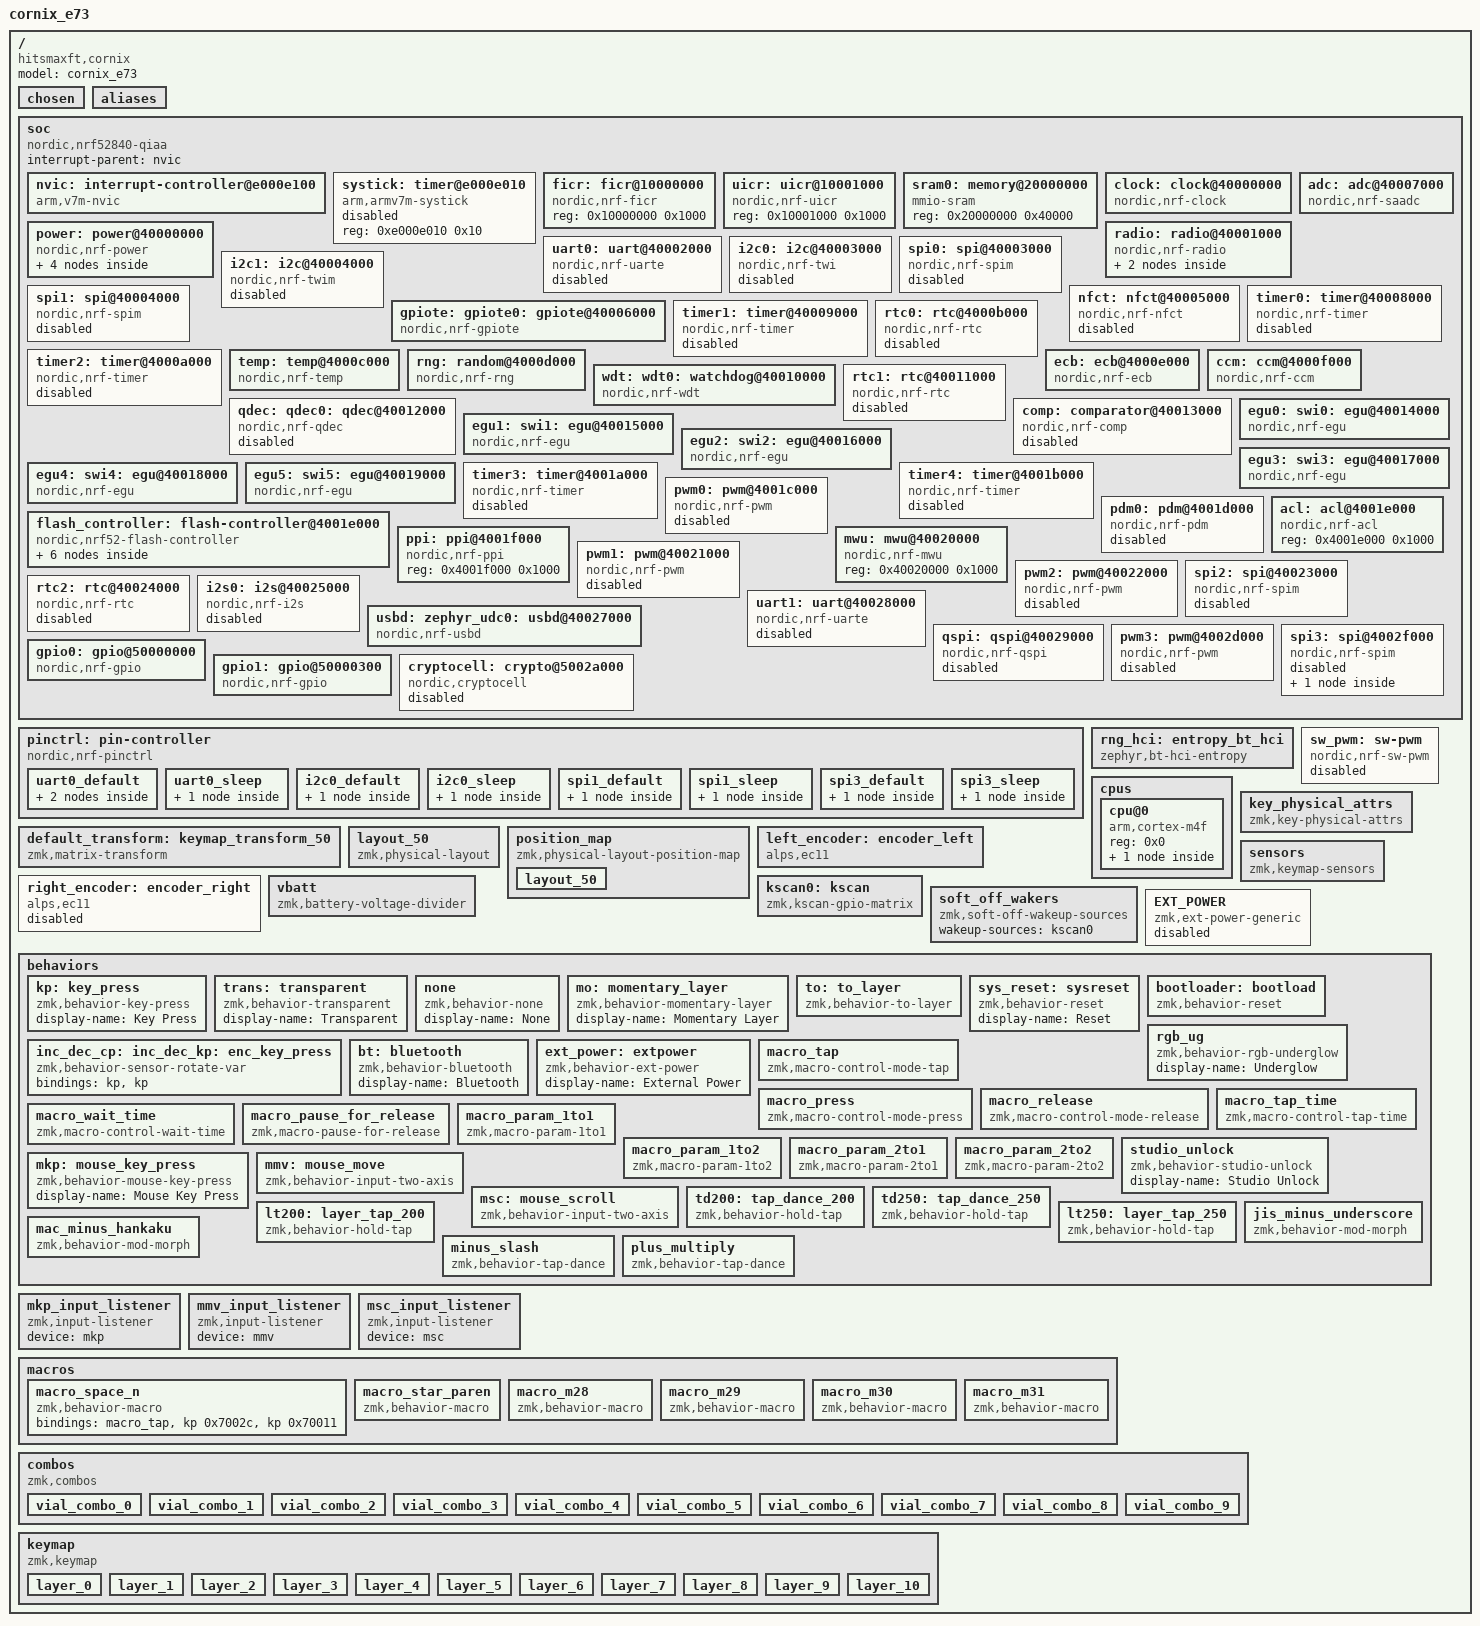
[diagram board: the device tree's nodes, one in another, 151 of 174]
/dts-v1/;

/ {
	#address-cells = < 0x1 >;
	#size-cells = < 0x1 >;
	model = "cornix_e73";
	compatible = "hitsmaxft,cornix";
	chosen {
		zephyr,bt-hci = &bt_hci_controller;
		zephyr,entropy = &rng;
		zephyr,flash-controller = &flash_controller;
		zephyr,code-partition = &code_partition;
		zephyr,sram = &sram0;
		zephyr,flash = &flash0;
		zmk,battery = &vbatt;
		zmk,kscan = &kscan0;
		zmk,physical-layout = &layout_50;
	};
	aliases {
	};
	soc {
		#address-cells = < 0x1 >;
		#size-cells = < 0x1 >;
		compatible = "nordic,nrf52840-qiaa", "nordic,nrf52840", "nordic,nrf52", "simple-bus";
		interrupt-parent = < &nvic >;
		ranges;
		nvic: interrupt-controller@e000e100 {
			#address-cells = < 0x1 >;
			compatible = "arm,v7m-nvic";
			reg = < 0xe000e100 0xc00 >;
			interrupt-controller;
			#interrupt-cells = < 0x2 >;
			arm,num-irq-priority-bits = < 0x3 >;
			phandle = < 0x1 >;
		};
		systick: timer@e000e010 {
			compatible = "arm,armv7m-systick";
			reg = < 0xe000e010 0x10 >;
			status = "disabled";
		};
		ficr: ficr@10000000 {
			compatible = "nordic,nrf-ficr";
			reg = < 0x10000000 0x1000 >;
			#nordic,ficr-cells = < 0x1 >;
			status = "okay";
		};
		uicr: uicr@10001000 {
			compatible = "nordic,nrf-uicr";
			reg = < 0x10001000 0x1000 >;
			status = "okay";
		};
		sram0: memory@20000000 {
			compatible = "mmio-sram";
			reg = < 0x20000000 0x40000 >;
		};
		clock: clock@40000000 {
			compatible = "nordic,nrf-clock";
			reg = < 0x40000000 0x1000 >;
			interrupts = < 0x0 0x1 >;
			status = "okay";
		};
		power: power@40000000 {
			compatible = "nordic,nrf-power";
			reg = < 0x40000000 0x1000 >;
			interrupts = < 0x0 0x1 >;
			status = "okay";
			#address-cells = < 0x1 >;
			#size-cells = < 0x1 >;
			gpregret1: gpregret1@4000051c {
				#address-cells = < 0x1 >;
				#size-cells = < 0x1 >;
				compatible = "nordic,nrf-gpregret";
				reg = < 0x4000051c 0x1 >;
				status = "okay";
			};
			gpregret2: gpregret2@40000520 {
				#address-cells = < 0x1 >;
				#size-cells = < 0x1 >;
				compatible = "nordic,nrf-gpregret";
				reg = < 0x40000520 0x1 >;
				status = "okay";
			};
			reg1: regulator@40000578 {
				compatible = "nordic,nrf5x-regulator";
				reg = < 0x40000578 0x1 >;
				regulator-name = "REG1";
				regulator-initial-mode = < 0x0 >;
			};
			reg0: regulator@40000580 {
				compatible = "nordic,nrf52x-regulator-hv";
				reg = < 0x40000580 0x1 >;
				regulator-name = "REG0";
				status = "disabled";
			};
		};
		radio: radio@40001000 {
			compatible = "nordic,nrf-radio";
			reg = < 0x40001000 0x1000 >;
			interrupts = < 0x1 0x1 >;
			status = "okay";
			ieee802154-supported;
			ble-2mbps-supported;
			ble-coded-phy-supported;
			tx-high-power-supported;
			ieee802154: ieee802154 {
				compatible = "nordic,nrf-ieee802154";
				status = "disabled";
			};
			bt_hci_controller: bt_hci_controller {
				compatible = "zephyr,bt-hci-ll-sw-split";
				status = "okay";
			};
		};
		uart0: uart@40002000 {
			compatible = "nordic,nrf-uarte";
			reg = < 0x40002000 0x1000 >;
			interrupts = < 0x2 0x1 >;
			status = "disabled";
			current-speed = < 0x1c200 >;
			pinctrl-0 = < &uart0_default >;
			pinctrl-1 = < &uart0_sleep >;
			pinctrl-names = "default", "sleep";
		};
		i2c0: i2c@40003000 {
			compatible = "nordic,nrf-twi";
			#address-cells = < 0x1 >;
			#size-cells = < 0x0 >;
			reg = < 0x40003000 0x1000 >;
			interrupts = < 0x3 0x1 >;
			easydma-maxcnt-bits = < 0x10 >;
			status = "disabled";
			zephyr,pm-device-runtime-auto;
			pinctrl-0 = < &i2c0_default >;
			pinctrl-1 = < &i2c0_sleep >;
			pinctrl-names = "default", "sleep";
		};
		spi0: spi@40003000 {
			compatible = "nordic,nrf-spim";
			#address-cells = < 0x1 >;
			#size-cells = < 0x0 >;
			reg = < 0x40003000 0x1000 >;
			interrupts = < 0x3 0x1 >;
			max-frequency = < 0x7a1200 >;
			easydma-maxcnt-bits = < 0x10 >;
			status = "disabled";
		};
		i2c1: i2c@40004000 {
			compatible = "nordic,nrf-twim";
			#address-cells = < 0x1 >;
			#size-cells = < 0x0 >;
			reg = < 0x40004000 0x1000 >;
			interrupts = < 0x4 0x1 >;
			easydma-maxcnt-bits = < 0x10 >;
			status = "disabled";
			zephyr,pm-device-runtime-auto;
		};
		spi1: spi@40004000 {
			compatible = "nordic,nrf-spim";
			#address-cells = < 0x1 >;
			#size-cells = < 0x0 >;
			reg = < 0x40004000 0x1000 >;
			interrupts = < 0x4 0x1 >;
			max-frequency = < 0x7a1200 >;
			easydma-maxcnt-bits = < 0x10 >;
			status = "disabled";
			pinctrl-0 = < &spi1_default >;
			pinctrl-1 = < &spi1_sleep >;
			pinctrl-names = "default", "sleep";
		};
		nfct: nfct@40005000 {
			compatible = "nordic,nrf-nfct";
			reg = < 0x40005000 0x1000 >;
			interrupts = < 0x5 0x1 >;
			status = "disabled";
		};
		gpiote: gpiote0: gpiote@40006000 {
			compatible = "nordic,nrf-gpiote";
			reg = < 0x40006000 0x1000 >;
			interrupts = < 0x6 0x5 >;
			status = "okay";
			instance = < 0x0 >;
			phandle = < 0xa >;
		};
		adc: adc@40007000 {
			compatible = "nordic,nrf-saadc";
			reg = < 0x40007000 0x1000 >;
			interrupts = < 0x7 0x1 >;
			status = "okay";
			#io-channel-cells = < 0x1 >;
			zephyr,pm-device-runtime-auto;
			phandle = < 0x12 >;
		};
		timer0: timer@40008000 {
			compatible = "nordic,nrf-timer";
			status = "disabled";
			reg = < 0x40008000 0x1000 >;
			cc-num = < 0x4 >;
			max-bit-width = < 0x20 >;
			interrupts = < 0x8 0x1 >;
			prescaler = < 0x0 >;
		};
		timer1: timer@40009000 {
			compatible = "nordic,nrf-timer";
			status = "disabled";
			reg = < 0x40009000 0x1000 >;
			cc-num = < 0x4 >;
			max-bit-width = < 0x20 >;
			interrupts = < 0x9 0x1 >;
			prescaler = < 0x0 >;
			phandle = < 0xb >;
		};
		timer2: timer@4000a000 {
			compatible = "nordic,nrf-timer";
			status = "disabled";
			reg = < 0x4000a000 0x1000 >;
			cc-num = < 0x4 >;
			max-bit-width = < 0x20 >;
			interrupts = < 0xa 0x1 >;
			prescaler = < 0x0 >;
		};
		rtc0: rtc@4000b000 {
			compatible = "nordic,nrf-rtc";
			reg = < 0x4000b000 0x1000 >;
			cc-num = < 0x3 >;
			interrupts = < 0xb 0x1 >;
			status = "disabled";
			clock-frequency = < 0x8000 >;
			prescaler = < 0x1 >;
		};
		temp: temp@4000c000 {
			compatible = "nordic,nrf-temp";
			reg = < 0x4000c000 0x1000 >;
			interrupts = < 0xc 0x1 >;
			status = "okay";
		};
		rng: random@4000d000 {
			compatible = "nordic,nrf-rng";
			reg = < 0x4000d000 0x1000 >;
			interrupts = < 0xd 0x1 >;
			status = "okay";
		};
		ecb: ecb@4000e000 {
			compatible = "nordic,nrf-ecb";
			reg = < 0x4000e000 0x1000 >;
			interrupts = < 0xe 0x1 >;
			status = "okay";
		};
		ccm: ccm@4000f000 {
			compatible = "nordic,nrf-ccm";
			reg = < 0x4000f000 0x1000 >;
			interrupts = < 0xf 0x1 >;
			length-field-length-8-bits;
			status = "okay";
		};
		wdt: wdt0: watchdog@40010000 {
			compatible = "nordic,nrf-wdt";
			reg = < 0x40010000 0x1000 >;
			interrupts = < 0x10 0x1 >;
			status = "okay";
		};
		rtc1: rtc@40011000 {
			compatible = "nordic,nrf-rtc";
			reg = < 0x40011000 0x1000 >;
			cc-num = < 0x4 >;
			interrupts = < 0x11 0x1 >;
			status = "disabled";
			clock-frequency = < 0x8000 >;
			prescaler = < 0x1 >;
		};
		qdec: qdec0: qdec@40012000 {
			compatible = "nordic,nrf-qdec";
			reg = < 0x40012000 0x1000 >;
			interrupts = < 0x12 0x1 >;
			status = "disabled";
		};
		comp: comparator@40013000 {
			compatible = "nordic,nrf-comp";
			reg = < 0x40013000 0x1000 >;
			interrupts = < 0x13 0x1 >;
			status = "disabled";
		};
		egu0: swi0: egu@40014000 {
			compatible = "nordic,nrf-egu", "nordic,nrf-swi";
			reg = < 0x40014000 0x1000 >;
			interrupts = < 0x14 0x1 >;
			status = "okay";
		};
		egu1: swi1: egu@40015000 {
			compatible = "nordic,nrf-egu", "nordic,nrf-swi";
			reg = < 0x40015000 0x1000 >;
			interrupts = < 0x15 0x1 >;
			status = "okay";
		};
		egu2: swi2: egu@40016000 {
			compatible = "nordic,nrf-egu", "nordic,nrf-swi";
			reg = < 0x40016000 0x1000 >;
			interrupts = < 0x16 0x1 >;
			status = "okay";
		};
		egu3: swi3: egu@40017000 {
			compatible = "nordic,nrf-egu", "nordic,nrf-swi";
			reg = < 0x40017000 0x1000 >;
			interrupts = < 0x17 0x1 >;
			status = "okay";
		};
		egu4: swi4: egu@40018000 {
			compatible = "nordic,nrf-egu", "nordic,nrf-swi";
			reg = < 0x40018000 0x1000 >;
			interrupts = < 0x18 0x1 >;
			status = "okay";
		};
		egu5: swi5: egu@40019000 {
			compatible = "nordic,nrf-egu", "nordic,nrf-swi";
			reg = < 0x40019000 0x1000 >;
			interrupts = < 0x19 0x1 >;
			status = "okay";
		};
		timer3: timer@4001a000 {
			compatible = "nordic,nrf-timer";
			status = "disabled";
			reg = < 0x4001a000 0x1000 >;
			cc-num = < 0x6 >;
			max-bit-width = < 0x20 >;
			interrupts = < 0x1a 0x1 >;
			prescaler = < 0x0 >;
		};
		timer4: timer@4001b000 {
			compatible = "nordic,nrf-timer";
			status = "disabled";
			reg = < 0x4001b000 0x1000 >;
			cc-num = < 0x6 >;
			max-bit-width = < 0x20 >;
			interrupts = < 0x1b 0x1 >;
			prescaler = < 0x0 >;
		};
		pwm0: pwm@4001c000 {
			compatible = "nordic,nrf-pwm";
			reg = < 0x4001c000 0x1000 >;
			interrupts = < 0x1c 0x1 >;
			status = "disabled";
			#pwm-cells = < 0x3 >;
		};
		pdm0: pdm@4001d000 {
			compatible = "nordic,nrf-pdm";
			reg = < 0x4001d000 0x1000 >;
			interrupts = < 0x1d 0x1 >;
			status = "disabled";
		};
		acl: acl@4001e000 {
			compatible = "nordic,nrf-acl";
			reg = < 0x4001e000 0x1000 >;
			status = "okay";
		};
		flash_controller: flash-controller@4001e000 {
			compatible = "nordic,nrf52-flash-controller";
			reg = < 0x4001e000 0x1000 >;
			partial-erase;
			#address-cells = < 0x1 >;
			#size-cells = < 0x1 >;
			flash0: flash@0 {
				compatible = "soc-nv-flash";
				erase-block-size = < 0x1000 >;
				write-block-size = < 0x4 >;
				reg = < 0x0 0x100000 >;
				partitions {
					compatible = "fixed-partitions";
					#address-cells = < 0x1 >;
					#size-cells = < 0x1 >;
					sd_partition: partition@0 {
						reg = < 0x0 0x1000 >;
					};
					code_partition: partition@1000 {
						reg = < 0x1000 0xd3000 >;
					};
					storage_partition: partition@d4000 {
						reg = < 0xd4000 0x20000 >;
					};
					boot_partition: partition@f4000 {
						reg = < 0xf4000 0xc000 >;
					};
				};
			};
		};
		ppi: ppi@4001f000 {
			compatible = "nordic,nrf-ppi";
			reg = < 0x4001f000 0x1000 >;
			status = "okay";
		};
		mwu: mwu@40020000 {
			compatible = "nordic,nrf-mwu";
			reg = < 0x40020000 0x1000 >;
			status = "okay";
		};
		pwm1: pwm@40021000 {
			compatible = "nordic,nrf-pwm";
			reg = < 0x40021000 0x1000 >;
			interrupts = < 0x21 0x1 >;
			status = "disabled";
			#pwm-cells = < 0x3 >;
		};
		pwm2: pwm@40022000 {
			compatible = "nordic,nrf-pwm";
			reg = < 0x40022000 0x1000 >;
			interrupts = < 0x22 0x1 >;
			status = "disabled";
			#pwm-cells = < 0x3 >;
		};
		spi2: spi@40023000 {
			compatible = "nordic,nrf-spim";
			#address-cells = < 0x1 >;
			#size-cells = < 0x0 >;
			reg = < 0x40023000 0x1000 >;
			interrupts = < 0x23 0x1 >;
			max-frequency = < 0x7a1200 >;
			easydma-maxcnt-bits = < 0x10 >;
			status = "disabled";
		};
		rtc2: rtc@40024000 {
			compatible = "nordic,nrf-rtc";
			reg = < 0x40024000 0x1000 >;
			cc-num = < 0x4 >;
			interrupts = < 0x24 0x1 >;
			status = "disabled";
			clock-frequency = < 0x8000 >;
			prescaler = < 0x1 >;
		};
		i2s0: i2s@40025000 {
			compatible = "nordic,nrf-i2s";
			#address-cells = < 0x1 >;
			#size-cells = < 0x0 >;
			reg = < 0x40025000 0x1000 >;
			interrupts = < 0x25 0x1 >;
			status = "disabled";
		};
		usbd: zephyr_udc0: usbd@40027000 {
			compatible = "nordic,nrf-usbd";
			reg = < 0x40027000 0x1000 >;
			interrupts = < 0x27 0x1 >;
			num-bidir-endpoints = < 0x1 >;
			num-in-endpoints = < 0x7 >;
			num-out-endpoints = < 0x7 >;
			num-isoin-endpoints = < 0x1 >;
			num-isoout-endpoints = < 0x1 >;
			status = "okay";
		};
		uart1: uart@40028000 {
			compatible = "nordic,nrf-uarte";
			reg = < 0x40028000 0x1000 >;
			interrupts = < 0x28 0x1 >;
			status = "disabled";
		};
		qspi: qspi@40029000 {
			compatible = "nordic,nrf-qspi";
			#address-cells = < 0x1 >;
			#size-cells = < 0x0 >;
			reg = < 0x40029000 0x1000 >, < 0x12000000 0x8000000 >;
			reg-names = "qspi", "qspi_mm";
			interrupts = < 0x29 0x1 >;
			status = "disabled";
		};
		pwm3: pwm@4002d000 {
			compatible = "nordic,nrf-pwm";
			reg = < 0x4002d000 0x1000 >;
			interrupts = < 0x2d 0x1 >;
			status = "disabled";
			#pwm-cells = < 0x3 >;
		};
		spi3: spi@4002f000 {
			compatible = "nordic,nrf-spim";
			#address-cells = < 0x1 >;
			#size-cells = < 0x0 >;
			reg = < 0x4002f000 0x1000 >;
			interrupts = < 0x2f 0x1 >;
			max-frequency = < 0x1e84800 >;
			easydma-maxcnt-bits = < 0x10 >;
			rx-delay-supported;
			rx-delay = < 0x2 >;
			status = "disabled";
			pinctrl-0 = < &spi3_default >;
			pinctrl-1 = < &spi3_sleep >;
			pinctrl-names = "default", "sleep";
			ws2812@0 {
				status = "disabled";
				compatible = "worldsemi,ws2812-spi";
				reg = < 0x0 >;
				spi-max-frequency = < 0x61a800 >;
				reset-delay = < 0x46 >;
				chain-length = < 0x2 >;
				spi-one-frame = < 0xf8 >;
				spi-zero-frame = < 0x80 >;
				color-mapping = < 0x2 0x1 0x3 >;
			};
		};
		gpio0: gpio@50000000 {
			compatible = "nordic,nrf-gpio";
			gpio-controller;
			reg = < 0x50000000 0x200 0x50000500 0x300 >;
			#gpio-cells = < 0x2 >;
			status = "okay";
			port = < 0x0 >;
			gpiote-instance = < &gpiote >;
			phandle = < 0x13 >;
		};
		gpio1: gpio@50000300 {
			compatible = "nordic,nrf-gpio";
			gpio-controller;
			reg = < 0x50000300 0x200 0x50000800 0x300 >;
			#gpio-cells = < 0x2 >;
			ngpios = < 0x10 >;
			status = "okay";
			port = < 0x1 >;
			gpiote-instance = < &gpiote >;
			phandle = < 0xf >;
		};
		cryptocell: crypto@5002a000 {
			compatible = "nordic,cryptocell", "arm,cryptocell-310";
			reg = < 0x5002a000 0x1000 >, < 0x5002b000 0x1000 >;
			reg-names = "wrapper", "core";
			interrupts = < 0x2a 0x1 >;
			status = "disabled";
		};
	};
	pinctrl: pin-controller {
		compatible = "nordic,nrf-pinctrl";
		uart0_default: uart0_default {
			phandle = < 0x2 >;
			group1 {
				psels = < 0x1000008 >;
				bias-pull-up;
			};
			group2 {
				psels = < 0x6 >;
			};
		};
		uart0_sleep: uart0_sleep {
			phandle = < 0x3 >;
			group1 {
				psels = < 0x1000008 >, < 0x6 >;
				low-power-enable;
			};
		};
		i2c0_default: i2c0_default {
			phandle = < 0x4 >;
			group1 {
				psels = < 0xc00000f >, < 0xb000011 >;
			};
		};
		i2c0_sleep: i2c0_sleep {
			phandle = < 0x5 >;
			group1 {
				psels = < 0xc00000f >, < 0xb000011 >;
				low-power-enable;
			};
		};
		spi1_default: spi1_default {
			phandle = < 0x6 >;
			group1 {
				psels = < 0x400002d >, < 0x500001c >, < 0x6000003 >;
			};
		};
		spi1_sleep: spi1_sleep {
			phandle = < 0x7 >;
			group1 {
				psels = < 0x400002d >, < 0x500001c >, < 0x6000003 >;
				low-power-enable;
			};
		};
		spi3_default: spi3_default {
			phandle = < 0x8 >;
			group1 {
				psels = < 0x5000018 >;
			};
		};
		spi3_sleep: spi3_sleep {
			phandle = < 0x9 >;
			group1 {
				psels = < 0x5000018 >;
				low-power-enable;
			};
		};
	};
	rng_hci: entropy_bt_hci {
		compatible = "zephyr,bt-hci-entropy";
		status = "okay";
	};
	sw_pwm: sw-pwm {
		compatible = "nordic,nrf-sw-pwm";
		status = "disabled";
		generator = < &timer1 >;
		clock-prescaler = < 0x0 >;
		#pwm-cells = < 0x3 >;
	};
	cpus {
		#address-cells = < 0x1 >;
		#size-cells = < 0x0 >;
		cpu@0 {
			device_type = "cpu";
			compatible = "arm,cortex-m4f";
			reg = < 0x0 >;
			#address-cells = < 0x1 >;
			#size-cells = < 0x1 >;
			itm: itm@e0000000 {
				compatible = "arm,armv7m-itm";
				reg = < 0xe0000000 0x1000 >;
				swo-ref-frequency = < 0x1e84800 >;
			};
		};
	};
	key_physical_attrs: key_physical_attrs {
		compatible = "zmk,key-physical-attrs";
		#key-cells = < 0x7 >;
		phandle = < 0xd >;
	};
	default_transform: keymap_transform_50 {
		compatible = "zmk,matrix-transform";
		columns = < 0xe >;
		rows = < 0x4 >;
		map = < 0x0 0x1 0x2 0x3 0x4 0x5 0xc 0xb 0xa 0x9 0x8 0x7 0x100 0x101 0x102 0x103 0x104 0x105 0x10c 0x10b 0x10a 0x109 0x108 0x107 0x200 0x201 0x202 0x203 0x204 0x205 0x206 0x10d 0x20c 0x20b 0x20a 0x209 0x208 0x207 0x300 0x301 0x302 0x303 0x304 0x305 0x30c 0x30b 0x30a 0x309 0x308 0x307 >;
		phandle = < 0xc >;
	};
	layout_50: layout_50 {
		compatible = "zmk,physical-layout";
		display-name = "LAYOUT_50";
		transform = < &default_transform >;
		keys = < &key_physical_attrs 0x64 0x64 0x0 0x32 0x0 0x0 0x0 >, < &key_physical_attrs 0x64 0x64 0x64 0x32 0x0 0x0 0x0 >, < &key_physical_attrs 0x64 0x64 0xc8 0x19 0x0 0x0 0x0 >, < &key_physical_attrs 0x64 0x64 0x12c 0x0 0x0 0x0 0x0 >, < &key_physical_attrs 0x64 0x64 0x190 0x19 0x0 0x0 0x0 >, < &key_physical_attrs 0x64 0x64 0x1f4 0x32 0x0 0x0 0x0 >, < &key_physical_attrs 0x64 0x64 0x352 0x32 0x0 0x0 0x0 >, < &key_physical_attrs 0x64 0x64 0x3b6 0x1e 0x0 0x0 0x0 >, < &key_physical_attrs 0x64 0x64 0x41a 0x0 0x0 0x0 0x0 >, < &key_physical_attrs 0x64 0x64 0x47e 0x21 0x0 0x0 0x0 >, < &key_physical_attrs 0x64 0x64 0x4e2 0x32 0x0 0x0 0x0 >, < &key_physical_attrs 0x64 0x64 0x546 0x32 0x0 0x0 0x0 >, < &key_physical_attrs 0x64 0x64 0x0 0x96 0x0 0x0 0x0 >, < &key_physical_attrs 0x64 0x64 0x64 0x96 0x0 0x0 0x0 >, < &key_physical_attrs 0x64 0x64 0xc8 0x7d 0x0 0x0 0x0 >, < &key_physical_attrs 0x64 0x64 0x12c 0x64 0x0 0x0 0x0 >, < &key_physical_attrs 0x64 0x64 0x190 0x7d 0x0 0x0 0x0 >, < &key_physical_attrs 0x64 0x64 0x1f4 0x96 0x0 0x0 0x0 >, < &key_physical_attrs 0x64 0x64 0x352 0x96 0x0 0x0 0x0 >, < &key_physical_attrs 0x64 0x64 0x3b6 0x82 0x0 0x0 0x0 >, < &key_physical_attrs 0x64 0x64 0x41a 0x64 0x0 0x0 0x0 >, < &key_physical_attrs 0x64 0x64 0x47e 0x85 0x0 0x0 0x0 >, < &key_physical_attrs 0x64 0x64 0x4e2 0x96 0x0 0x0 0x0 >, < &key_physical_attrs 0x64 0x64 0x546 0x96 0x0 0x0 0x0 >, < &key_physical_attrs 0x64 0x64 0x0 0xff 0x0 0x0 0x0 >, < &key_physical_attrs 0x64 0x64 0x64 0xff 0x0 0x0 0x0 >, < &key_physical_attrs 0x64 0x64 0xc8 0xe1 0x0 0x0 0x0 >, < &key_physical_attrs 0x64 0x64 0x12c 0xc8 0x0 0x0 0x0 >, < &key_physical_attrs 0x64 0x64 0x190 0xe1 0x0 0x0 0x0 >, < &key_physical_attrs 0x64 0x64 0x1f4 0xff 0x0 0x0 0x0 >, < &key_physical_attrs 0x64 0x64 0x258 0xc8 0x0 0x0 0x0 >, < &key_physical_attrs 0x64 0x64 0x2ee 0xc8 0x0 0x0 0x0 >, < &key_physical_attrs 0x64 0x64 0x352 0xff 0x0 0x0 0x0 >, < &key_physical_attrs 0x64 0x64 0x3b6 0xe6 0x0 0x0 0x0 >, < &key_physical_attrs 0x64 0x64 0x41a 0xc8 0x0 0x0 0x0 >, < &key_physical_attrs 0x64 0x64 0x47e 0xe9 0x0 0x0 0x0 >, < &key_physical_attrs 0x64 0x64 0x4e2 0xff 0x0 0x0 0x0 >, < &key_physical_attrs 0x64 0x64 0x546 0xff 0x0 0x0 0x0 >, < &key_physical_attrs 0x64 0x64 0x0 0x163 0x0 0x0 0x0 >, < &key_physical_attrs 0x64 0x64 0x64 0x163 0x0 0x0 0x0 >, < &key_physical_attrs 0x64 0x64 0xc8 0x14a 0x0 0x0 0x0 >, < &key_physical_attrs 0x64 0x64 0x15e 0x16b 0x0 0x0 0x0 >, < &key_physical_attrs 0x64 0x64 0x1c2 0x172 0x4a9 0x1f4 0x1db >, < &key_physical_attrs 0x64 0x64 0x226 0x16d 0x8fc 0x1f4 0x1db >, < &key_physical_attrs 0x64 0x64 0x2fc 0x21a 0xfffff704 0x1f4 0x1db >, < &key_physical_attrs 0x64 0x64 0x384 0x177 0xfffffb57 0x39d 0x1db >, < &key_physical_attrs 0x64 0x64 0x3e8 0x16b 0x0 0x0 0x0 >, < &key_physical_attrs 0x64 0x64 0x47e 0x152 0x0 0x0 0x0 >, < &key_physical_attrs 0x64 0x64 0x4e2 0x163 0x0 0x0 0x0 >, < &key_physical_attrs 0x64 0x64 0x546 0x163 0x0 0x0 0x0 >;
		phandle = < 0xe >;
	};
	position_map {
		compatible = "zmk,physical-layout-position-map";
		layout_50 {
			physical-layout = < &layout_50 >;
			positions = < 0x0 0x1 0x2 0x3 0x4 0x5 0x6 0x7 0x8 0x9 0xa 0xb >, < 0xc 0xd 0xe 0xf 0x10 0x11 0x12 0x13 0x14 0x15 0x16 0x17 >, < 0x18 0x19 0x1a 0x1b 0x1c 0x1d 0x1e 0x1f 0x20 0x21 0x22 0x23 0x24 0x25 >, < 0x26 0x27 0x28 0x29 0x2a 0x2b 0x2c 0x2d 0x2e 0x2f 0x30 0x31 >;
		};
	};
	left_encoder: encoder_left {
		compatible = "alps,ec11";
		a-gpios = < &gpio1 0x4 0x10 >;
		b-gpios = < &gpio1 0x6 0x10 >;
		steps = < 0x50 >;
		status = "okay";
		phandle = < 0x10 >;
	};
	right_encoder: encoder_right {
		compatible = "alps,ec11";
		a-gpios = < &gpio1 0x4 0x10 >;
		b-gpios = < &gpio1 0x6 0x10 >;
		steps = < 0x50 >;
		status = "disabled";
		phandle = < 0x11 >;
	};
	sensors: sensors {
		compatible = "zmk,keymap-sensors";
		sensors = < &left_encoder &right_encoder >;
		triggers-per-rotation = < 0x14 >;
	};
	vbatt: vbatt {
		compatible = "zmk,battery-voltage-divider";
		io-channels = < &adc 0x3 >;
		output-ohms = < 0x1e8480 >;
		full-ohms = < 0x2ad0f0 >;
	};
	kscan0: kscan {
		compatible = "zmk,kscan-gpio-matrix";
		diode-direction = "col2row";
		wakeup-source;
		row-gpios = < &gpio0 0x1e 0x20 >, < &gpio0 0x1f 0x20 >, < &gpio0 0x1d 0x20 >, < &gpio0 0x2 0x20 >;
		col-gpios = < &gpio0 0x1c 0x0 >, < &gpio0 0x3 0x0 >, < &gpio1 0xa 0x0 >, < &gpio1 0xb 0x0 >, < &gpio1 0xd 0x0 >, < &gpio0 0x9 0x0 >, < &gpio0 0xa 0x0 >;
		phandle = < 0x14 >;
	};
	soft_off_wakers {
		compatible = "zmk,soft-off-wakeup-sources";
		wakeup-sources = < &kscan0 >;
	};
	EXT_POWER {
		status = "disabled";
		compatible = "zmk,ext-power-generic";
		control-gpios = < &gpio0 0xd 0x0 >;
		init-delay-ms = < 0x32 >;
	};
	behaviors {
		kp: key_press {
			compatible = "zmk,behavior-key-press";
			#binding-cells = < 0x1 >;
			display-name = "Key Press";
			phandle = < 0x15 >;
		};
		trans: transparent {
			compatible = "zmk,behavior-transparent";
			#binding-cells = < 0x0 >;
			display-name = "Transparent";
			phandle = < 0x2d >;
		};
		none: none {
			compatible = "zmk,behavior-none";
			#binding-cells = < 0x0 >;
			display-name = "None";
			phandle = < 0x1b >;
		};
		mo: momentary_layer {
			compatible = "zmk,behavior-momentary-layer";
			#binding-cells = < 0x1 >;
			display-name = "Momentary Layer";
			phandle = < 0x16 >;
		};
		to: to_layer {
			compatible = "zmk,behavior-to-layer";
			#binding-cells = < 0x1 >;
			display-name = "To Layer";
			locking;
			phandle = < 0x20 >;
		};
		sys_reset: sysreset {
			compatible = "zmk,behavior-reset";
			#binding-cells = < 0x0 >;
			display-name = "Reset";
		};
		bootloader: bootload {
			compatible = "zmk,behavior-reset";
			type = < 0x57 >;
			bootloader;
			#binding-cells = < 0x0 >;
			display-name = "Bootloader";
		};
		inc_dec_cp: inc_dec_kp: enc_key_press {
			compatible = "zmk,behavior-sensor-rotate-var";
			#sensor-binding-cells = < 0x2 >;
			bindings = < &kp >, < &kp >;
			phandle = < 0x22 >;
		};
		rgb_ug: rgb_ug {
			compatible = "zmk,behavior-rgb-underglow";
			#binding-cells = < 0x2 >;
			display-name = "Underglow";
		};
		bt: bluetooth {
			compatible = "zmk,behavior-bluetooth";
			#binding-cells = < 0x2 >;
			display-name = "Bluetooth";
			phandle = < 0x2c >;
		};
		ext_power: extpower {
			compatible = "zmk,behavior-ext-power";
			#binding-cells = < 0x1 >;
			display-name = "External Power";
		};
		macro_tap: macro_tap {
			compatible = "zmk,macro-control-mode-tap";
			#binding-cells = < 0x0 >;
			phandle = < 0x1a >;
		};
		macro_press: macro_press {
			compatible = "zmk,macro-control-mode-press";
			#binding-cells = < 0x0 >;
		};
		macro_release: macro_release {
			compatible = "zmk,macro-control-mode-release";
			#binding-cells = < 0x0 >;
		};
		macro_tap_time: macro_tap_time {
			compatible = "zmk,macro-control-tap-time";
			#binding-cells = < 0x1 >;
		};
		macro_wait_time: macro_wait_time {
			compatible = "zmk,macro-control-wait-time";
			#binding-cells = < 0x1 >;
		};
		macro_pause_for_release: macro_pause_for_release {
			compatible = "zmk,macro-pause-for-release";
			#binding-cells = < 0x0 >;
		};
		macro_param_1to1: macro_param_1to1 {
			compatible = "zmk,macro-param-1to1";
			#binding-cells = < 0x0 >;
		};
		macro_param_1to2: macro_param_1to2 {
			compatible = "zmk,macro-param-1to2";
			#binding-cells = < 0x0 >;
		};
		macro_param_2to1: macro_param_2to1 {
			compatible = "zmk,macro-param-2to1";
			#binding-cells = < 0x0 >;
		};
		macro_param_2to2: macro_param_2to2 {
			compatible = "zmk,macro-param-2to2";
			#binding-cells = < 0x0 >;
		};
		studio_unlock: studio_unlock {
			compatible = "zmk,behavior-studio-unlock";
			#binding-cells = < 0x0 >;
			display-name = "Studio Unlock";
		};
		mkp: mouse_key_press {
			compatible = "zmk,behavior-mouse-key-press";
			#binding-cells = < 0x1 >;
			display-name = "Mouse Key Press";
			phandle = < 0x17 >;
		};
		mmv: mouse_move {
			compatible = "zmk,behavior-input-two-axis";
			#binding-cells = < 0x1 >;
			x-input-code = < 0x0 >;
			y-input-code = < 0x1 >;
			time-to-max-speed-ms = < 0x12c >;
			acceleration-exponent = < 0x1 >;
			phandle = < 0x18 >;
		};
		msc: mouse_scroll {
			compatible = "zmk,behavior-input-two-axis";
			#binding-cells = < 0x1 >;
			x-input-code = < 0x6 >;
			y-input-code = < 0x8 >;
			time-to-max-speed-ms = < 0x12c >;
			acceleration-exponent = < 0x0 >;
			phandle = < 0x19 >;
		};
		td200: tap_dance_200 {
			compatible = "zmk,behavior-hold-tap";
			#binding-cells = < 0x2 >;
			bindings = < &kp >, < &kp >;
			flavor = "tap-preferred";
			tapping-term-ms = < 0xc8 >;
			phandle = < 0x1c >;
		};
		td250: tap_dance_250 {
			compatible = "zmk,behavior-hold-tap";
			#binding-cells = < 0x2 >;
			bindings = < &kp >, < &kp >;
			flavor = "tap-preferred";
			tapping-term-ms = < 0xfa >;
			phandle = < 0x1d >;
		};
		lt200: layer_tap_200 {
			compatible = "zmk,behavior-hold-tap";
			#binding-cells = < 0x2 >;
			bindings = < &mo >, < &kp >;
			flavor = "tap-preferred";
			tapping-term-ms = < 0xc8 >;
			phandle = < 0x1e >;
		};
		lt250: layer_tap_250 {
			compatible = "zmk,behavior-hold-tap";
			#binding-cells = < 0x2 >;
			bindings = < &mo >, < &kp >;
			flavor = "tap-preferred";
			tapping-term-ms = < 0xfa >;
			phandle = < 0x21 >;
		};
		jis_minus_underscore: jis_minus_underscore {
			compatible = "zmk,behavior-mod-morph";
			#binding-cells = < 0x0 >;
			bindings = < &kp 0x7002d >, < &kp 0x2070087 >;
			mods = < 0x22 >;
			phandle = < 0x25 >;
		};
		mac_minus_hankaku: mac_minus_hankaku {
			compatible = "zmk,behavior-mod-morph";
			#binding-cells = < 0x0 >;
			bindings = < &kp 0x7002d >, < &kp 0x1070033 >;
			mods = < 0x11 >;
			phandle = < 0x1f >;
		};
		minus_slash: minus_slash {
			compatible = "zmk,behavior-tap-dance";
			#binding-cells = < 0x0 >;
			bindings = < &kp 0x70056 >, < &kp 0x70054 >;
			tapping-term-ms = < 0xc8 >;
			phandle = < 0x23 >;
		};
		plus_multiply: plus_multiply {
			compatible = "zmk,behavior-tap-dance";
			#binding-cells = < 0x0 >;
			bindings = < &kp 0x70057 >, < &kp 0x70055 >;
			tapping-term-ms = < 0xc8 >;
			phandle = < 0x24 >;
		};
	};
	mkp_input_listener: mkp_input_listener {
		compatible = "zmk,input-listener";
		device = < &mkp >;
	};
	mmv_input_listener: mmv_input_listener {
		compatible = "zmk,input-listener";
		device = < &mmv >;
	};
	msc_input_listener: msc_input_listener {
		compatible = "zmk,input-listener";
		device = < &msc >;
	};
	macros {
		macro_space_n: macro_space_n {
			compatible = "zmk,behavior-macro";
			#binding-cells = < 0x0 >;
			bindings = < &macro_tap &kp 0x7002c &kp 0x70011 >;
			phandle = < 0x26 >;
		};
		macro_star_paren: macro_star_paren {
			compatible = "zmk,behavior-macro";
			#binding-cells = < 0x0 >;
			bindings = < &macro_tap &kp 0x2070025 &kp 0x2070026 &kp 0x70050 >;
			phandle = < 0x27 >;
		};
		macro_m28: macro_m28 {
			compatible = "zmk,behavior-macro";
			#binding-cells = < 0x0 >;
			bindings = < &macro_tap &kp 0x70025 &kp 0x7001e &kp 0x70038 &kp 0x70027 &kp 0x7001e &kp 0x70038 &kp 0x70027 &kp 0x70025 >;
			phandle = < 0x28 >;
		};
		macro_m29: macro_m29 {
			compatible = "zmk,behavior-macro";
			#binding-cells = < 0x0 >;
			bindings = < &macro_tap &kp 0x2070004 &kp 0x70022 &kp 0x7001e &kp 0x70020 &kp 0x70021 >;
			phandle = < 0x29 >;
		};
		macro_m30: macro_m30 {
			compatible = "zmk,behavior-macro";
			#binding-cells = < 0x0 >;
			bindings = < &macro_tap &kp 0x207001e &kp 0x70014 &kp 0x70004 &kp 0x7001d &kp 0x7001f &kp 0x7001f &kp 0x70027 &kp 0x7001e >;
			phandle = < 0x2a >;
		};
		macro_m31: macro_m31 {
			compatible = "zmk,behavior-macro";
			#binding-cells = < 0x0 >;
			bindings = < &macro_tap &kp 0x7001e &kp 0x70014 &kp 0x70004 &kp 0x7001d &kp 0x7001f &kp 0x7001f &kp 0x70027 &kp 0x7001e >;
			phandle = < 0x2b >;
		};
	};
	combos {
		compatible = "zmk,combos";
		vial_combo_0 {
			bindings = < &kp 0x2070025 >;
			key-positions = < 0x7 0x8 >;
			layers = < 0x1 >;
			timeout-ms = < 0x32 >;
		};
		vial_combo_1 {
			bindings = < &kp 0x2070025 >;
			key-positions = < 0x7 0x8 >;
			layers = < 0x5 >;
			timeout-ms = < 0x32 >;
		};
		vial_combo_2 {
			bindings = < &kp 0x2070026 >;
			key-positions = < 0x8 0x9 >;
			layers = < 0x1 >;
			timeout-ms = < 0x32 >;
		};
		vial_combo_3 {
			bindings = < &kp 0x2070026 >;
			key-positions = < 0x8 0x9 >;
			layers = < 0x5 >;
			timeout-ms = < 0x32 >;
		};
		vial_combo_4 {
			bindings = < &kp 0x2070030 >;
			key-positions = < 0x13 0x14 >;
			layers = < 0x1 >;
			timeout-ms = < 0x32 >;
		};
		vial_combo_5 {
			bindings = < &kp 0x2070030 >;
			key-positions = < 0x13 0x14 >;
			layers = < 0x5 >;
			timeout-ms = < 0x32 >;
		};
		vial_combo_6 {
			bindings = < &kp 0x70030 >;
			key-positions = < 0x21 0x22 >;
			layers = < 0x1 >;
			timeout-ms = < 0x32 >;
		};
		vial_combo_7 {
			bindings = < &kp 0x70030 >;
			key-positions = < 0x21 0x22 >;
			layers = < 0x5 >;
			timeout-ms = < 0x32 >;
		};
		vial_combo_8 {
			bindings = < &kp 0x70032 >;
			key-positions = < 0x22 0x23 >;
			layers = < 0x1 >;
			timeout-ms = < 0x32 >;
		};
		vial_combo_9 {
			bindings = < &kp 0x70032 >;
			key-positions = < 0x22 0x23 >;
			layers = < 0x5 >;
			timeout-ms = < 0x32 >;
		};
	};
	keymap {
		compatible = "zmk,keymap";
		layer_0 {
			display-name = "Vial 0";
			bindings = < &none &td200 0x70029 0x70014 &kp 0x7001a &kp 0x70008 &kp 0x70015 &kp 0x70017 &kp 0x7001c &kp 0x70018 &kp 0x7000c &kp 0x70012 &kp 0x70013 &none &none &td250 0x8070004 0x70004 &td250 0xa070020 0x70016 &kp 0x70007 &kp 0x70009 &kp 0x7000a &kp 0x7000b &lt200 0x2 0x7000d &lt200 0x7 0x7000e &kp 0x7000f &mac_minus_hankaku &none &none &td250 0x807001d 0x7001d &kp 0x7001b &td250 0x8070006 0x70006 &td250 0x8070019 0x70019 &kp 0x70005 &kp 0xc00e2 &to 0x9 &kp 0x70011 &kp 0x70010 &kp 0x70036 &kp 0x70037 &kp 0x2070038 &none &to 0x2 &none &none &kp 0x700e0 &lt200 0x1 0x7002c &td200 0x700e1 0x7002b &td200 0x7004c 0x7002a &lt250 0x2 0x70028 &kp 0x107002c &none &none &none >;
			sensor-bindings = < &inc_dec_kp 0xc00ea 0xc00e9 >, < &inc_dec_kp 0x7004b 0x7004e >;
		};
		layer_1 {
			display-name = "Vial 1";
			bindings = < &none &kp 0x207001e &none &none &none &none &kp 0x70023 &kp 0x70024 &kp 0x70025 &kp 0x70026 &td250 0x2070022 0x70054 &none &none &td250 0x2070024 0x207001f &kp 0x70033 &kp 0x7003c &kp 0x70043 &kp 0x70044 &kp 0x2070020 &kp 0x70021 &kp 0x70022 &kp 0x70023 &minus_slash &none &none &none &none &kp 0x2070033 &none &none &none &to 0x9 &kp 0x207002d &kp 0x7001e &kp 0x7001f &kp 0x70020 &plus_multiply &none &none &none &none &none &none &none &td200 0x7004c 0x7002a &kp 0x70028 &kp 0x70027 &kp 0x70037 &kp 0x70055 &none >;
			sensor-bindings = < &inc_dec_kp 0x0 0x0 >, < &inc_dec_kp 0x7004b 0x7004e >;
		};
		layer_2 {
			display-name = "Vial 2";
			bindings = < &none &none &none &kp 0x70052 &none &none &none &none &kp 0x2070026 &kp 0x2070027 &none &none &none &none &kp 0x70050 &kp 0x70051 &kp 0x7004f &none &none &none &kp 0x207002f &kp 0x2070030 &none &none &none &none &none &none &none &none &none &none &none &none &kp 0x7002f &kp 0x70030 &none &none &to 0x0 &none &none &msc 0xfff6 &msc 0xa &msc 0xfff6 &none &none &msc 0xfff6 &none &none &none >;
			sensor-bindings = < &inc_dec_kp 0x0 0xc00e9 >, < &inc_dec_kp 0x7004b 0x7004e >;
		};
		layer_3 {
			display-name = "Vial 3";
			bindings = < &none &none &none &mmv 0xfda8 &none &none &none &none &none &none &none &none &none &none &mmv 0xfda80000 &mmv 0x258 &mmv 0x2580000 &none &none &mkp 0x1 &none &mkp 0x2 &none &none &none &none &none &kp 0x7001e &none &none &none &none &none &none &none &none &none &none &none &none &none &msc 0xfff6 &msc 0xa &msc 0xfff6 &none &kp 0x70028 &none &none &none &to 0x4 >;
			sensor-bindings = < &inc_dec_kp 0xc00ea 0xc00e9 >, < &inc_dec_kp 0x7004b 0x7004e >;
		};
		layer_4 {
			display-name = "Vial 4";
			bindings = < &kp 0x70029 &td200 0x70029 0x70014 &td250 0x807002b 0x7001a &kp 0x70008 &kp 0x70015 &kp 0x70017 &kp 0x7001c &kp 0x70018 &lt250 0x8 0x7000c &kp 0x70012 &kp 0x70013 &kp 0x7004c &kp 0x700e1 &td250 0x1070004 0x70004 &td250 0x70046 0x70016 &kp 0x70007 &kp 0x70009 &kp 0x7000a &kp 0x7000b &lt200 0x6 0x7000d &lt200 0x7 0x7000e &kp 0x7000f &jis_minus_underscore &kp 0x70087 &none &td250 0x107001d 0x7001d &kp 0x7001b &td250 0x1070006 0x70006 &td250 0x1070019 0x70019 &kp 0x70005 &kp 0xc00e2 &to 0x9 &kp 0x70011 &kp 0x70010 &kp 0x70036 &kp 0x70037 &kp 0x70038 &none &none &macro_space_n &kp 0x700e2 &kp 0x700e0 &lt200 0x5 0x7002c &td200 0x700e1 0x7002b &td200 0x7004c 0x7002a &kp 0x70028 &kp 0x70039 &kp 0x70040 &none &none >;
			sensor-bindings = < &inc_dec_kp 0xc00ea 0xc00e9 >, < &inc_dec_kp 0x7004b 0x7004e >;
		};
		layer_5 {
			display-name = "Vial 5";
			bindings = < &none &kp 0x207001e &none &none &none &kp 0x7004c &td250 0x8070023 0x70023 &td250 0x8070024 0x70024 &td250 0x8070025 0x70025 &td250 0x8070026 0x70026 &td250 0x2070022 0x70054 &none &none &td250 0x2070023 0x7002f &kp 0x70033 &kp 0x7003c &kp 0x70043 &kp 0x70044 &kp 0x2070020 &td250 0x8070021 0x70021 &td250 0x8070022 0x70022 &td250 0x8070023 0x70023 &minus_slash &kp 0x70031 &none &none &none &kp 0x70034 &kp 0x107001d &none &none &none &kp 0x207002d &td250 0x807001e 0x7001e &td250 0x807001f 0x7001f &td250 0x8070020 0x70020 &plus_multiply &none &none &none &none &none &none &none &td200 0x7004c 0x7002a &kp 0x70028 &td250 0x8070027 0x70027 &kp 0x70037 &kp 0x70055 &none >;
			sensor-bindings = < &inc_dec_kp 0xc00ea 0xc00e9 >, < &inc_dec_kp 0x7004b 0x7004e >;
		};
		layer_6 {
			display-name = "Vial 6";
			bindings = < &none &none &none &kp 0x70052 &none &none &none &none &kp 0x2070025 &kp 0x2070026 &macro_star_paren &none &none &none &kp 0x70050 &kp 0x70051 &kp 0x7004f &none &none &none &kp 0x2070030 &kp 0x2070031 &none &none &none &none &none &none &none &none &none &none &none &none &kp 0x70030 &kp 0x70031 &none &none &none &none &none &none &none &none &td200 0x7004c 0x7002a &none &none &none &none &none >;
			sensor-bindings = < &inc_dec_kp 0xc00ea 0xc00e9 >, < &inc_dec_kp 0x7004b 0x7004e >;
		};
		layer_7 {
			display-name = "Vial 7";
			bindings = < &none &none &none &mmv 0xfda8 &none &none &none &none &none &none &none &none &none &none &mmv 0xfda80000 &mmv 0x258 &mmv 0x2580000 &none &none &mkp 0x1 &none &mkp 0x2 &none &none &none &none &none &none &none &none &kp 0xc00e2 &to 0x9 &none &none &none &none &none &none &none &none &none &msc 0xfff6 &msc 0xa &msc 0xfff6 &none &mo 0xa &none &none &none &to 0x4 >;
			sensor-bindings = < &inc_dec_kp 0xc00ea 0xc00e9 >, < &inc_dec_kp 0x7004b 0x7004e >;
		};
		layer_8 {
			display-name = "Vial 8";
			bindings = < &none &none &none &none &none &none &none &none &none &none &none &none &none &none &none &none &none &none &none &macro_m28 &none &none &none &none &none &none &none &none &none &none &kp 0xc00e2 &mkp 0x4 &none &none &none &none &none &none &none &none &none &none &none &none &macro_m29 &macro_m30 &macro_m31 &none &none &none >;
			sensor-bindings = < &inc_dec_kp 0xc00ea 0xc00e9 >, < &inc_dec_kp 0x7004b 0x7004e >;
		};
		layer_9 {
			display-name = "Vial 9";
			bindings = < &none &none &bt 0x3 0x2 &none &none &none &none &none &bt 0x3 0x1 &none &none &bt 0x0 0x0 &none &none &none &none &none &none &none &none &none &none &none &none &none &none &none &none &none &none &none &none &none &bt 0x3 0x0 &none &none &none &none &none &none &none &to 0x4 &to 0x4 &to 0x4 &to 0x0 &to 0x0 &to 0x0 &none &none &none >;
			sensor-bindings = < &inc_dec_kp 0xc00ea 0xc00e9 >, < &inc_dec_kp 0x7004b 0x7004e >;
		};
		layer_10 {
			display-name = "Mouse Boost";
			bindings = < &trans &trans &trans &mmv 0xfb50 &trans &trans &trans &trans &trans &trans &trans &trans &trans &trans &mmv 0xfb500000 &mmv 0x4b0 &mmv 0x4b00000 &trans &trans &trans &trans &trans &trans &trans &trans &trans &trans &trans &trans &trans &trans &trans &trans &trans &trans &trans &trans &trans &trans &trans &trans &trans &trans &trans &trans &trans &trans &trans &trans &trans >;
			sensor-bindings = < &inc_dec_kp 0xc00ea 0xc00e9 >, < &inc_dec_kp 0x7004b 0x7004e >;
		};
	};
};
